VERSION "FR_RE_CANFD"

NS_ :

BS_:

BU_: ADCC ONEBOX RXCU

BO_ 56 VCU_COM_10: 16 RXCU
 SG_ VCU_10_CRC : 7|8@0+ (1,0) [0|255] "" ONEBOX
 SG_ VCU_10_RollgCntr : 11|4@0+ (1,0) [0|14] "" ONEBOX
 SG_ VCU_10_Resd : 15|4@0+ (1,0) [0|15] "" ONEBOX
 SG_ VCU_10_ShiftInProgress : 16|1@0+ (1,0) [0|1] "" Vector__XXX
 SG_ VCU_10_ShiftInProgressValidData : 17|1@0+ (1,0) [0|1] "" Vector__XXX
 SG_ VCU_10_TargetGear : 20|3@0+ (1,0) [0|7] "" Vector__XXX
 SG_ VCU_10_ActualGear : 23|3@0+ (1,0) [0|7] "" Vector__XXX
 SG_ VCU_10_TargetGearValidData : 28|1@0+ (1,0) [0|1] "" Vector__XXX
 SG_ VCU_10_ActualGearValidData : 29|1@0+ (1,0) [0|1] "" Vector__XXX
 SG_ VCU_10_BrakePedalStsValidData : 30|1@0+ (1,0) [0|1] "" Vector__XXX
 SG_ VCU_10_BrakePedalSts : 31|1@0+ (1,0) [0|1] "" Vector__XXX
 SG_ VCU_10_TowingMode : 49|2@0+ (1,0) [0|3] "" ONEBOX
 SG_ HCU_TCUR_GearShiftProgFlag : 63|2@0+ (1,0) [0|3] "" Vector__XXX
 SG_ VCU_10_CRC2 : 71|8@0+ (1,0) [0|255] "" Vector__XXX
 SG_ VCU_10_RollgCntr2 : 75|4@0+ (1,0) [0|14] "" Vector__XXX
 SG_ VCU_10_Resd2 : 79|4@0+ (1,0) [0|15] "" Vector__XXX

BO_ 59 VCU_ONEBOX_11: 64 RXCU
 SG_ VCU_11_CRC1 : 7|8@0+ (1,0) [0|255] "" Vector__XXX
 SG_ VCU_11_RollgCntr1 : 11|4@0+ (1,0) [0|14] "" Vector__XXX
 SG_ VCU_11_Resd1 : 15|4@0+ (1,0) [0|15] "" Vector__XXX
 SG_ VCU_11_IndicatedDriverReqWhlTqFA : 23|16@0+ (1,-32768) [-32768|32767] "NM" Vector__XXX
 SG_ VCU_11_ActWheelTorqueFA : 39|16@0+ (1,-32768) [-32768|32767] "NM" Vector__XXX
 SG_ VCU_11_ActWheelSpdFA : 55|16@0+ (1,-32767) [-32767|32767] "RPM" Vector__XXX
 SG_ VCU_11_CRC2 : 71|8@0+ (1,0) [0|255] "" Vector__XXX
 SG_ VCU_11_RollgCntr2 : 75|4@0+ (1,0) [0|14] "" Vector__XXX
 SG_ VCU_11_Resd2 : 79|4@0+ (1,0) [0|15] "" Vector__XXX
 SG_ VCU_11_IndcdDriverReqWhlTqStsFA : 80|1@0+ (1,0) [0|1] "" Vector__XXX
 SG_ VCU_11_ActWheelTorqueStsFA : 82|2@0+ (1,0) [0|3] "" Vector__XXX
 SG_ VCU_11_ActWheelSpdStsFA : 83|1@0+ (1,0) [0|1] "" Vector__XXX
 SG_ VCU_11_MotorReadyFMCU : 84|1@0+ (1,0) [0|1] "" Vector__XXX
 SG_ VCU_11_IndicatedDriverReqWhlTqRA : 95|16@0+ (1,-32768) [-32768|32767] "NM" Vector__XXX
 SG_ VCU_11_ActWheelTorqueRA : 111|16@0+ (1,-32768) [-32768|32767] "NM" Vector__XXX
 SG_ VCU_11_CRC3 : 135|8@0+ (1,0) [0|255] "" Vector__XXX
 SG_ VCU_11_RollgCntr3 : 139|4@0+ (1,0) [0|14] "" Vector__XXX
 SG_ VCU_11_Resd3 : 143|4@0+ (1,0) [0|15] "" Vector__XXX
 SG_ VCU_11_ActWheelSpdRA : 151|16@0+ (1,-32767) [-32767|32767] "RPM" Vector__XXX
 SG_ VCU_11_IndcdDriverReqWhlTqStsRA : 160|1@0+ (1,0) [0|1] "" Vector__XXX
 SG_ VCU_11_ActWheelTorqueStsRA : 162|2@0+ (1,0) [0|3] "" Vector__XXX
 SG_ VCU_11_MotorReadyRMCU : 163|1@0+ (1,0) [0|1] "" Vector__XXX
 SG_ VCU_11_ActWheelSpdStsRA : 164|1@0+ (1,0) [0|1] "" Vector__XXX
 SG_ VCU_11_MbRegenMaxWheel : 175|16@0+ (1,-32768) [-32768|32767] "NM" Vector__XXX
 SG_ VCU_11_CRC4 : 199|8@0+ (1,0) [0|255] "" ONEBOX
 SG_ VCU_11_RollgCntr4 : 203|4@0+ (1,0) [0|14] "" ONEBOX
 SG_ VCU_11_Resd4 : 207|4@0+ (1,0) [0|15] "" ONEBOX
 SG_ VCU_11_MbRegenWheel : 215|16@0+ (1,-32768) [-32768|32767] "NM" Vector__XXX
 SG_ VCU_11_MbRegenMaxWheelQualifier : 225|2@0+ (1,0) [0|3] "" Vector__XXX
 SG_ VCU_11_MbRegenWheelQualifier : 227|2@0+ (1,0) [0|3] "" Vector__XXX
 SG_ VCU_11_EPBReq : 229|2@0+ (1,0) [0|3] "" ONEBOX
 SG_ VCU_11_GasPedalPosInvalidData : 230|1@0+ (1,0) [0|1] "" Vector__XXX
 SG_ VCU_11_AcceleratorPosRawIVD : 231|1@0+ (1,0) [0|1] "" Vector__XXX
 SG_ VCU_11_GasPedalPosition : 239|10@0+ (0.1,0) [0|100] "%" Vector__XXX
 SG_ VCU_11_AcceleratorPosRaw : 245|10@0+ (0.1,0) [0|100] "%" Vector__XXX
 SG_ VCU_11_EPBReqValid : 251|1@0+ (1,0) [0|1] "" ONEBOX
 SG_ VCU_11_CRC5 : 263|8@0+ (1,0) [0|255] "" Vector__XXX
 SG_ VCU_11_RollgCntr5 : 267|4@0+ (1,0) [0|14] "" Vector__XXX
 SG_ VCU_11_Resd5 : 271|4@0+ (1,0) [0|15] "" Vector__XXX
 SG_ VCU_11_CoastRegenTargetWheelFA : 279|16@0+ (1,-32768) [-32768|32767] "NM" Vector__XXX
 SG_ VCU_11_CoastRegenTargetWheelFAQ : 295|2@0+ (1,0) [0|3] "" Vector__XXX
 SG_ VCU_11_CoastRegenTargetWheelRA : 303|16@0+ (1,-32768) [-32768|32767] "NM" Vector__XXX
 SG_ VCU_11_CoastRegenTargetWheelRAQ : 319|2@0+ (1,0) [0|3] "" Vector__XXX
 SG_ VCU_11_CRC6 : 327|8@0+ (1,0) [0|255] "" Vector__XXX
 SG_ VCU_11_RollgCntr6 : 331|4@0+ (1,0) [0|14] "" Vector__XXX
 SG_ VCU_11_Resd6 : 335|4@0+ (1,0) [0|15] "" Vector__XXX
 SG_ VCU_11_MaxWheelTorqueFA : 343|16@0+ (1,-32768) [-32768|32767] "NM" Vector__XXX
 SG_ VCU_11_MaxWheelTorqueRA : 359|16@0+ (1,-32768) [-32768|32767] "NM" Vector__XXX
 SG_ HCU_11_iTASRearTorque_Max : 375|16@0+ (1,-12000) [-12000|12000] "Nm" Vector__XXX
 SG_ VCU_11_CRC7 : 391|8@0+ (1,0) [0|255] "" Vector__XXX
 SG_ VCU_11_RollgCntr7 : 395|4@0+ (1,0) [0|14] "" Vector__XXX
 SG_ VCU_11_Resd7 : 399|4@0+ (1,0) [0|15] "" Vector__XXX
 SG_ VCU_11_OPDHoldRequest : 405|2@0+ (1,0) [0|3] "" Vector__XXX
 SG_ VCU_11_OPDHydBrkCompenRqSts : 406|1@0+ (1,0) [0|1] "" Vector__XXX
 SG_ VCU_11_OnePedalstatus : 407|1@0+ (1,0) [0|1] "" Vector__XXX
 SG_ VCU_11_OPDHydBrkCompenRqTq : 415|16@0+ (1,-65535) [-65535|0] "NM" Vector__XXX
 SG_ HCU_11_RearWheelDir : 426|2@0+ (1,0) [0|3] "" Vector__XXX
 SG_ VCU_11_DrivingModReq : 431|5@0+ (1,0) [0|31] "" Vector__XXX
 SG_ HCU_11_iTASFrontTorque_Max : 439|16@0+ (1,-12000) [-12000|12000] "Nm" Vector__XXX
 SG_ VCU_11_CRC8 : 455|8@0+ (1,0) [0|255] "" Vector__XXX
 SG_ VCU_11_RollgCntr8 : 459|4@0+ (1,0) [0|14] "" Vector__XXX
 SG_ VCU_11_Resd8 : 463|4@0+ (1,0) [0|15] "" Vector__XXX

BO_ 323 HCU_HW_143h: 48 RXCU
 SG_ HCU_CRC1_143h : 7|8@0+ (1,0) [0|255] "" ADCC
 SG_ HCU_RollgCntr1_143h : 11|4@0+ (1,0) [0|14] "" ADCC
 SG_ HCU_Resd1_143h : 15|4@0+ (1,0) [0|15] "" ADCC
 SG_ HCU_ErrorFb_143h : 18|3@0+ (1,0) [0|7] "" ADCC
 SG_ HCU_GearShiftAvl_143h : 19|1@0+ (1,0) [0|1] "" ADCC
 SG_ HCU_VehWhlReqTqVld_143h : 20|1@0+ (1,0) [0|1] "" ADCC
 SG_ HCU_EGSGearShiftReq_143h : 23|3@0+ (1,0) [0|7] "" ADCC
 SG_ HCU_VehWhlReqTq_143h : 31|16@0+ (1,-32768) [-32768|32767] "" ADCC
 SG_ HCU_CIMGearShiftReq_143h : 49|3@0+ (1,0) [0|7] "" ADCC
 SG_ HCU_ECGPOvrdInvalidData_143h : 61|1@0+ (1,0) [0|1] "" ADCC
 SG_ HCU_ECGPOvrd_143h : 62|1@0+ (1,0) [0|1] "" ADCC
 SG_ HCU_CRC2_143h : 71|8@0+ (1,0) [0|255] "" ADCC
 SG_ HCU_RollgCntr2_143h : 75|4@0+ (1,0) [0|14] "" ADCC
 SG_ HCU_Resd2_143h : 79|4@0+ (1,0) [0|15] "" ADCC
 SG_ HCU_FMCUStandstill_143h : 80|1@0+ (1,0) [0|1] "" ADCC
 SG_ HCU_FMCUModActvSt_143h : 82|2@0+ (1,0) [0|3] "" ADCC
 SG_ HCU_FMCU_SpdSvModAvl_143h : 83|1@0+ (1,0) [0|1] "" ADCC
 SG_ HCU_FMCU_ModeSt_143h : 87|4@0+ (1,0) [0|15] "" ADCC
 SG_ HCU_FMCU_SpdAct_143h : 95|16@0+ (1,-32767) [-32767|32766] "rpm" ADCC
 SG_ HCU_FMCUActRUnfilteredRodSpd : 111|16@0+ (1,-30000) [-30000|35535] "RPM" ADCC
 SG_ HCU_FMCUSpdActVld_143h : 120|1@0+ (1,0) [0|1] "" ADCC
 SG_ HCU_FMCUSpdSVModFlt_143h : 123|3@0+ (1,0) [0|7] "" ADCC
 SG_ HCU_FMCUVehSldSt_143h : 124|1@0+ (1,0) [0|1] "" ADCC
 SG_ HCU_FMCUBlkSt_143h : 127|3@0+ (1,0) [0|7] "" ADCC
 SG_ HCU_CRC3_143h : 135|8@0+ (1,0) [0|255] "" ADCC
 SG_ HCU_RollgCntr3_143h : 139|4@0+ (1,0) [0|14] "" ADCC
 SG_ HCU_Resd3_143h : 143|4@0+ (1,0) [0|15] "" ADCC
 SG_ HCU_ISGStandstill_143h : 144|1@0+ (1,0) [0|1] "" ADCC
 SG_ HCU_ISGModActvSt_143h : 146|2@0+ (1,0) [0|3] "" ADCC
 SG_ HCU_ISGSpdSvModAvl_143h : 147|1@0+ (1,0) [0|1] "" ADCC
 SG_ HCU_ISGF_ModeSt_143h : 151|4@0+ (1,0) [0|15] "" ADCC
 SG_ HCU_ISGF_SpdAct_143h : 159|16@0+ (1,-32767) [-32767|32766] "rpm" ADCC
 SG_ HCU_ISGActRUnfilteredRodSpd : 175|16@0+ (1,-30000) [-30000|35535] "RPM" ADCC
 SG_ HCU_ISGF_SpdActVld_143h : 184|1@0+ (1,0) [0|1] "" ADCC
 SG_ HCU_ISGSpdSVModFlt_143h : 187|3@0+ (1,0) [0|7] "" ADCC
 SG_ HCU_ISGVehSldSt_143h : 188|1@0+ (1,0) [0|1] "" ADCC
 SG_ HCU_ISGBlkSt_143h : 191|3@0+ (1,0) [0|7] "" ADCC
 SG_ HCU_CRC4_143h : 199|8@0+ (1,0) [0|255] "" ADCC
 SG_ HCU_RollgCntr4_143h : 203|4@0+ (1,0) [0|14] "" ADCC
 SG_ HCU_Resd4_143h : 207|4@0+ (1,0) [0|15] "" ADCC
 SG_ HCU_RMCUStandstill_143h : 208|1@0+ (1,0) [0|1] "" ADCC
 SG_ HCU_RMCUModActvSt_143h : 210|2@0+ (1,0) [0|3] "" ADCC
 SG_ HCU_RMCU_SpdSvModAvl_143h : 211|1@0+ (1,0) [0|1] "" ADCC
 SG_ HCU_RMCU_State_143h : 215|4@0+ (1,0) [0|15] "" ADCC
 SG_ HCU_RMCU_Speed_143h : 223|16@0+ (1,-32767) [-32767|32766] "rpm" ADCC
 SG_ HCU_RMCUActRUnfilteredRodSpd : 239|16@0+ (1,-30000) [-30000|35535] "RPM" ADCC
 SG_ HCU_RMCU_SpeedVld_143h : 248|1@0+ (1,0) [0|1] "" ADCC
 SG_ HCU_RMCUSpdSVModFlt_143h : 251|3@0+ (1,0) [0|7] "" ADCC
 SG_ HCU_RMCUVehSldSt_143h : 252|1@0+ (1,0) [0|1] "" ADCC
 SG_ HCU_RMCU_MCUBlkSt_143h : 255|3@0+ (1,0) [0|7] "" ADCC
 SG_ HCU_CRC5_143h : 263|8@0+ (1,0) [0|255] "" ADCC
 SG_ HCU_RollgCntr5_143h : 267|4@0+ (1,0) [0|14] "" ADCC
 SG_ HCU_Resd5_143h : 271|4@0+ (1,0) [0|15] "" ADCC
 SG_ HCU_RMCUReqTq_143h : 279|14@0+ (1,-5000) [-5000|11383] "Nm" ADCC
 SG_ HCU_FMCUReqTq_143h : 281|14@0+ (1,-5000) [-5000|11383] "Nm" ADCC
 SG_ HCU_ISGFReqTq_143h : 299|14@0+ (1,-5000) [-5000|11383] "Nm" ADCC
 SG_ HCU_CRC6_143h : 327|8@0+ (1,0) [0|255] "" ADCC
 SG_ HCU_RollgCntr6_143h : 331|4@0+ (1,0) [0|14] "" ADCC
 SG_ HCU_Resd6_143h : 335|4@0+ (1,0) [0|15] "" ADCC

BO_ 324 HCU_HW_144h: 32 RXCU
 SG_ VCU_MotorDrvCaplTqWhlFA : 23|16@0+ (1,-32768) [-32768|32767] "NM" ADCC
 SG_ VCU_MotorRgnCaplTqWhlFA : 39|16@0+ (1,-32768) [-32768|32767] "NM" ADCC
 SG_ VCU_MotorDrvCaplTqWhlRA : 55|16@0+ (1,-32768) [-32768|32767] "NM" ADCC
 SG_ VCU_MotorRgnCaplTqWhlRA : 87|16@0+ (1,-32768) [-32768|32767] "NM" ADCC

BO_ 555 ONEBOX_3: 48 ONEBOX
 SG_ ONEBOX_3_CRC4 : 199|8@0+ (1,0) [0|255] "" RXCU
 SG_ ONEBOX_3_RollgCntr4 : 203|4@0+ (1,0) [0|14] "" RXCU
 SG_ ONEBOX_3_Resd4 : 207|4@0+ (1,0) [0|15] "" RXCU
 SG_ BrakePedalPressStsValidData : 240|1@0+ (1,0) [0|1] "" RXCU
 SG_ BrakePedalPressSts : 255|2@0+ (1,0) [0|3] "" RXCU

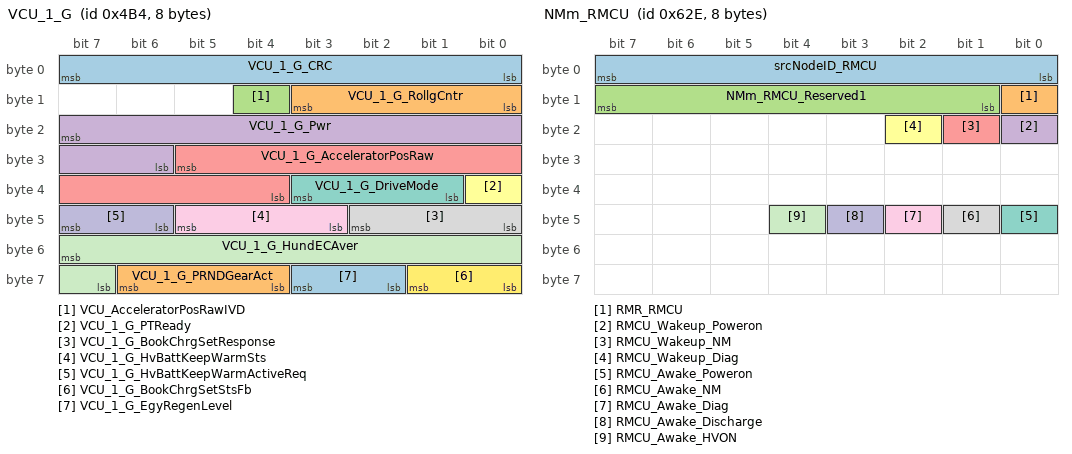
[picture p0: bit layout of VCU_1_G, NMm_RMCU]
BO_ 1204 VCU_1_G: 8 RXCU
 SG_ VCU_1_G_CRC : 7|8@0+ (1,0) [0|255] "" ADCC
 SG_ VCU_1_G_RollgCntr : 11|4@0+ (1,0) [0|14] "" ADCC
 SG_ VCU_AcceleratorPosRawIVD : 12|1@0+ (1,0) [0|1] "" Vector__XXX
 SG_ VCU_1_G_Pwr : 23|10@0+ (1,-500) [-500|500] "" ADCC
 SG_ VCU_1_G_AcceleratorPosRaw : 29|10@0+ (0.1,0) [0|100] "%" ADCC
 SG_ VCU_1_G_PTReady : 32|1@0+ (1,0) [0|1] "" ADCC,ONEBOX
 SG_ VCU_1_G_DriveMode : 35|3@0+ (1,0) [0|7] "" ADCC
 SG_ VCU_1_G_BookChrgSetResponse : 42|3@0+ (1,0) [0|7] "" Vector__XXX
 SG_ VCU_1_G_HvBattKeepWarmSts : 45|3@0+ (1,0) [0|7] "" Vector__XXX
 SG_ VCU_1_G_HvBattKeepWarmActiveReq : 47|2@0+ (1,0) [0|3] "" Vector__XXX
 SG_ VCU_1_G_HundECAver : 55|9@0+ (0.1,0) [0|51] "kwh" ADCC
 SG_ VCU_1_G_BookChrgSetStsFb : 57|2@0+ (1,0) [0|3] "" Vector__XXX
 SG_ VCU_1_G_EgyRegenLevel : 59|2@0+ (1,0) [0|3] "" ADCC
 SG_ VCU_1_G_PRNDGearAct : 62|3@0+ (1,0) [0|7] "" ADCC

BO_ 1209 VCU_2_G: 8 RXCU
 SG_ VCU_2_G_CRC : 7|8@0+ (1,0) [0|255] "" ADCC
 SG_ VCU_2_G_RollgCntr : 11|4@0+ (1,0) [0|14] "" ADCC
 SG_ VCU_2_G_Resd : 15|4@0+ (1,0) [0|15] "" ADCC
 SG_ VCU_2_G_GasPedalPosInvalidData : 24|1@0+ (1,0) [0|1] "" ADCC
 SG_ VCU_2_G_PowerLimit : 25|1@0+ (1,0) [0|1] "" ADCC
 SG_ VCU_2_G_BrakeLightReq : 26|1@0+ (1,0) [0|1] "" ADCC
 SG_ VCU_2_G_VehicleSystemFailure : 27|1@0+ (1,0) [0|1] "" ADCC
 SG_ OnekeyHVOffSuccess_4B9h : 28|1@0+ (1,0) [0|1] "" Vector__XXX
 SG_ VCU_2_G_BootloadSts : 29|1@0+ (1,0) [0|1] "" ADCC
 SG_ VCU_2_G_DischgSts : 30|1@0+ (1,0) [0|1] "" ADCC
 SG_ VCU_2_G_BrakePedalStsValidData : 31|1@0+ (1,0) [0|1] "" ADCC
 SG_ VCU_2_G_ExhibitionMod : 32|1@0+ (1,0) [0|1] "" Vector__XXX
 SG_ VCU_2_G_BrakePedalSts : 36|1@0+ (1,0) [0|1] "" ADCC
 SG_ VCU_2_G_DCDCEnable : 37|1@0+ (1,0) [0|1] "" ADCC
 SG_ VCU_2_G_HVReady : 38|1@0+ (1,0) [0|1] "" ADCC
 SG_ Res_VCU_2_G_Brake_state : 39|1@0+ (1,0) [0|1] "" ADCC
 SG_ VCU_2_G_VCUEnergyflow : 43|4@0+ (1,0) [0|15] "" ADCC
 SG_ VCU_2_G_GasPedalPosition : 49|10@0+ (0.1,0) [0|100] "%" ADCC
 SG_ VCU_2_G_DrvGearShiftFailureIndcn : 53|4@0+ (1,0) [0|15] "" ADCC
 SG_ VCU_2_G_OnekeyHVoffStyle : 55|2@0+ (1,0) [0|3] "" Vector__XXX

BO_ 1582 NMm_RMCU: 8 RXCU
 SG_ srcNodeID_RMCU : 7|8@0+ (1,0) [0|255] "" Vector__XXX
 SG_ RMR_RMCU : 8|1@0+ (1,0) [0|1] "" Vector__XXX
 SG_ NMm_RMCU_Reserved1 : 15|7@0+ (1,0) [0|127] "" Vector__XXX
 SG_ RMCU_Wakeup_Poweron : 16|1@0+ (1,0) [0|1] "" Vector__XXX
 SG_ RMCU_Wakeup_NM : 17|1@0+ (1,0) [0|1] "" Vector__XXX
 SG_ RMCU_Wakeup_Diag : 18|1@0+ (1,0) [0|1] "" Vector__XXX
 SG_ RMCU_Awake_Poweron : 40|1@0+ (1,0) [0|1] "" Vector__XXX
 SG_ RMCU_Awake_NM : 41|1@0+ (1,0) [0|1] "" Vector__XXX
 SG_ RMCU_Awake_Diag : 42|1@0+ (1,0) [0|1] "" Vector__XXX
 SG_ RMCU_Awake_Discharge : 43|1@0+ (1,0) [0|1] "" Vector__XXX
 SG_ RMCU_Awake_HVON : 44|1@0+ (1,0) [0|1] "" Vector__XXX

CM_ SG_ 56 VCU_10_CRC "Profile1A:E2E CRC (SAE J1850 CRC-8) for 8 Bytes
DataID:0x0068";
CM_ SG_ 56 VCU_10_RollgCntr "Profile1A:E2E Rolling message counter(the maximum value of Alive counter is 14)";
CM_ SG_ 56 VCU_10_Resd "Profile1A:E2E Reserved";
CM_ SG_ 56 VCU_10_ShiftInProgress "shifting progress judgement";
CM_ SG_ 56 VCU_10_ShiftInProgressValidData "shifting progress judgement validation";
CM_ SG_ 56 VCU_10_TargetGear "目标档位
Target gear";
CM_ SG_ 56 VCU_10_ActualGear "实际档位
actual gear";
CM_ SG_ 56 VCU_10_TargetGearValidData "目标档位有效性
valid Target gear";
CM_ SG_ 56 VCU_10_ActualGearValidData "实际档位有效性
valid actual gear";
CM_ SG_ 56 VCU_10_BrakePedalStsValidData "制动踏板状态有效";
CM_ SG_ 56 VCU_10_BrakePedalSts "制动踏板状态";
CM_ SG_ 56 VCU_10_TowingMode "拖车模式";
CM_ SG_ 56 HCU_TCUR_GearShiftProgFlag "捷途新增RSCU相关换挡信号The shifting status of rear gearbox（ONEBOX接收）";
CM_ SG_ 56 VCU_10_CRC2 "Profile1A:E2E CRC (SAE J1850 CRC-8) for 8 Bytes
DataID:0x01BB";
CM_ SG_ 56 VCU_10_RollgCntr2 "Profile1A:E2E Rolling message counter(the maximum value of Alive counter is 14)";
CM_ SG_ 56 VCU_10_Resd2 "Profile1A:E2E Reserved";
CM_ SG_ 59 VCU_11_CRC1 "Profile1A:E2E CRC (SAE J1850 CRC-8) for 8 Bytes
DataID:0x0069";
CM_ SG_ 59 VCU_11_RollgCntr1 "Profile1A:E2E Rolling message counter(the maximum value of Alive counter is 14)";
CM_ SG_ 59 VCU_11_Resd1 "Profile1A:E2E Reserved";
CM_ SG_ 59 VCU_11_IndicatedDriverReqWhlTqFA "前轴需求轮端扭矩
Driver request wheel torque at FA";
CM_ SG_ 59 VCU_11_ActWheelTorqueFA "前轴实际轮端扭矩
Actual wheel torque at FA";
CM_ SG_ 59 VCU_11_ActWheelSpdFA "前轮转速（基于电机转速计算）
The motor terminal speed, forward and backward are both sent the positive value";
CM_ SG_ 59 VCU_11_CRC2 "Profile1A:E2E CRC (SAE J1850 CRC-8) for 8 Bytes
DataID:0x006A";
CM_ SG_ 59 VCU_11_RollgCntr2 "Profile1A:E2E Rolling message counter(the maximum value of Alive counter is 14)";
CM_ SG_ 59 VCU_11_Resd2 "Profile1A:E2E Reserved";
CM_ SG_ 59 VCU_11_IndcdDriverReqWhlTqStsFA "前轴需求轮端扭矩有效
Driver request wheel torque status at FA";
CM_ SG_ 59 VCU_11_ActWheelTorqueStsFA "前轴实际轮端扭矩有效
Actual wheel torque status at FA";
CM_ SG_ 59 VCU_11_ActWheelSpdStsFA "前轮转速有效
Actual wheel speed status at FA";
CM_ SG_ 59 VCU_11_MotorReadyFMCU "When the high voltage power-on of the motor is complete and there is no fault, 'Ready' will be sent, other conditions,'Not Ready'will be sent";
CM_ SG_ 59 VCU_11_IndicatedDriverReqWhlTqRA "后轴需求轮端扭矩
Driver request wheel torque at RA";
CM_ SG_ 59 VCU_11_ActWheelTorqueRA "后轴实际轮端扭矩
Actual wheel torque at RA";
CM_ SG_ 59 VCU_11_CRC3 "Profile1A:E2E CRC (SAE J1850 CRC-8) for 8 Bytes
DataID:0x006B";
CM_ SG_ 59 VCU_11_RollgCntr3 "Profile1A:E2E Rolling message counter(the maximum value of Alive counter is 14)";
CM_ SG_ 59 VCU_11_Resd3 "Profile1A:E2E Reserved";
CM_ SG_ 59 VCU_11_ActWheelSpdRA "后轮转速（基于电机转速计算）
The motor terminal speed, forward and backward are both sent the positive value";
CM_ SG_ 59 VCU_11_IndcdDriverReqWhlTqStsRA "后轴需求轮端扭矩有效
Driver request wheel torque status at RA";
CM_ SG_ 59 VCU_11_ActWheelTorqueStsRA "后轴实际轮端扭矩有效
Actual wheel torque status at RA";
CM_ SG_ 59 VCU_11_MotorReadyRMCU "When the high voltage power-on of the motor is complete and there is no fault, 'Ready' will be sent, other conditions,'Not Ready'will be sent";
CM_ SG_ 59 VCU_11_ActWheelSpdStsRA "后轮转速有效
Actual wheel speed status at RA";
CM_ SG_ 59 VCU_11_MbRegenMaxWheel "Max regen torque potential";
CM_ SG_ 59 VCU_11_CRC4 "Profile1A:E2E CRC (SAE J1850 CRC-8) for 8 Bytes
DataID:0x006C";
CM_ SG_ 59 VCU_11_RollgCntr4 "Profile1A:E2E Rolling message counter(the maximum value of Alive counter is 14)";
CM_ SG_ 59 VCU_11_Resd4 "Profile1A:E2E Reserved";
CM_ SG_ 59 VCU_11_MbRegenWheel "Actual regen torque";
CM_ SG_ 59 VCU_11_MbRegenMaxWheelQualifier "Max regen torque potential status";
CM_ SG_ 59 VCU_11_MbRegenWheelQualifier "Actual regen torque status";
CM_ SG_ 59 VCU_11_EPBReq "VCU request EPB function";
CM_ SG_ 59 VCU_11_GasPedalPosition "Driver/Cruise control
This signal including compositive informations which are actual gas pedal position and dummy Cruise control gas pedal position";
CM_ SG_ 59 VCU_11_AcceleratorPosRaw "Raw position of the accelerator pedal (unfiltered). Represents always raw pedal position without any other influcence only mandatory to calculated gradient acceleration pedal.";
CM_ SG_ 59 VCU_11_CRC5 "Profile1A:E2E CRC (SAE J1850 CRC-8) for 8 Bytes
DataID:0x01B7";
CM_ SG_ 59 VCU_11_RollgCntr5 "Profile1A:E2E Rolling message counter(the maximum value of Alive counter is 14)";
CM_ SG_ 59 VCU_11_Resd5 "Profile1A:E2E Reserved";
CM_ SG_ 59 VCU_11_CoastRegenTargetWheelFA "Coast regen target torque at wheel";
CM_ SG_ 59 VCU_11_CoastRegenTargetWheelFAQ "Coast regen target torque status at wheel";
CM_ SG_ 59 VCU_11_CoastRegenTargetWheelRA "Coast regen target torque at wheel";
CM_ SG_ 59 VCU_11_CoastRegenTargetWheelRAQ "Coast regen target torque status at wheel";
CM_ SG_ 59 VCU_11_CRC6 "Profile1A:E2E CRC (SAE J1850 CRC-8) for 8 Bytes
DataID:0x01B6";
CM_ SG_ 59 VCU_11_RollgCntr6 "Profile1A:E2E Rolling message counter(the maximum value of Alive counter is 14)";
CM_ SG_ 59 VCU_11_Resd6 "Profile1A:E2E Reserved";
CM_ SG_ 59 HCU_11_iTASRearTorque_Max "iTAS功能HCU可提供后轴最大扭矩";
CM_ SG_ 59 VCU_11_CRC7 "Profile1A:E2E CRC (SAE J1850 CRC-8) for 8 Bytes
DataID:0x01B5";
CM_ SG_ 59 VCU_11_RollgCntr7 "Profile1A:E2E Rolling message counter(the maximum value of Alive counter is 14)";
CM_ SG_ 59 VCU_11_Resd7 "Profile1A:E2E Reserved";
CM_ SG_ 59 VCU_11_OPDHoldRequest "车辆静止状态请求";
CM_ SG_ 59 VCU_11_OPDHydBrkCompenRqSts "液压制动补偿请求状态";
CM_ SG_ 59 VCU_11_OnePedalstatus "单踏板模式开启状态（底盘专用）";
CM_ SG_ 59 VCU_11_OPDHydBrkCompenRqTq "液压制动补偿力矩";
CM_ SG_ 59 HCU_11_RearWheelDir "HCU反馈后轴扭矩方向";
CM_ SG_ 59 VCU_11_DrivingModReq "HCU给IPB映射驾驶模式";
CM_ SG_ 59 HCU_11_iTASFrontTorque_Max "iTAS功能HCU可提供前轴最大扭矩";
CM_ SG_ 59 VCU_11_CRC8 "Profile1A:E2E CRC (SAE J1850 CRC-8) for 8 Bytes
DataID:0x01B4";
CM_ SG_ 59 VCU_11_RollgCntr8 "Profile1A:E2E Rolling message counter(the maximum value of Alive counter is 14)";
CM_ SG_ 59 VCU_11_Resd8 "Profile1A:E2E Reserved";
CM_ SG_ 323 HCU_CRC1_143h "Profile1A:E2E CRC (SAE J1850 CRC-8) for 8 Bytes
DataID:0x00FA";
CM_ SG_ 323 HCU_RollgCntr1_143h "Profile1A:E2E Rolling message counter(the maximum value of Alive counter is 14)";
CM_ SG_ 323 HCU_Resd1_143h "Profile1A:E2E Reserved";
CM_ SG_ 323 HCU_ErrorFb_143h "HCU上报故障原因
0x0:No error
0x1: ADS请求有效位无效
0x2: 高压故障
0x2: MCU故障
0x3: BMS故障
0x7:ADS E2E 故障或者time out";
CM_ SG_ 323 HCU_GearShiftAvl_143h "挡位切换可用状态";
CM_ SG_ 323 HCU_VehWhlReqTqVld_143h "整车需求轮端扭矩有效";
CM_ SG_ 323 HCU_EGSGearShiftReq_143h "电子换挡器挡位请求";
CM_ SG_ 323 HCU_VehWhlReqTq_143h "整车需求轮端扭矩";
CM_ SG_ 323 HCU_CIMGearShiftReq_143h "电子换挡器挡位请求";
CM_ SG_ 323 HCU_ECGPOvrdInvalidData_143h "标识驾驶员扭矩高于ACC请求扭矩有效性";
CM_ SG_ 323 HCU_ECGPOvrd_143h "标识驾驶员扭矩高于ACC请求扭矩";
CM_ SG_ 323 HCU_CRC2_143h "Profile1A:E2E CRC (SAE J1850 CRC-8) for 8 Bytes
DataID:0x00FB";
CM_ SG_ 323 HCU_RollgCntr2_143h "Profile1A:E2E Rolling message counter(the maximum value of Alive counter is 14)";
CM_ SG_ 323 HCU_Resd2_143h "Profile1A:E2E Reserved";
CM_ SG_ 323 HCU_FMCUStandstill_143h "MCU standstill状态";
CM_ SG_ 323 HCU_FMCUModActvSt_143h "MCU模式激活状态
0x0: 扭矩模式
0x1: 转速模式
0x2: SV模式";
CM_ SG_ 323 HCU_FMCU_SpdSvModAvl_143h "转速模式可用状态";
CM_ SG_ 323 HCU_FMCU_ModeSt_143h "前驱动电机状态信号
actual state of FMCU motor
FMCU状态信号
拆帧转发至GL 网段
ID 0x397（FLZCU_16）Bit116-119";
CM_ SG_ 323 HCU_FMCU_SpdAct_143h "FMCU motor actual speed
前驱动电机实际转速（EM2转速）";
CM_ SG_ 323 HCU_FMCUActRUnfilteredRodSpd "MCU滤波前实际转速";
CM_ SG_ 323 HCU_FMCUSpdActVld_143h "VCU转发FMCU电机实际转速有效性";
CM_ SG_ 323 HCU_FMCUSpdSVModFlt_143h "MCU转速模式故障原因
0x0: 无故障
0x1: 输出扭矩绝对值过大故障";
CM_ SG_ 323 HCU_FMCUVehSldSt_143h "驱动电机判断车辆是否溜车";
CM_ SG_ 323 HCU_FMCUBlkSt_143h "MCU卡停状态";
CM_ SG_ 323 HCU_CRC3_143h "Profile1A:E2E CRC (SAE J1850 CRC-8) for 8 Bytes
DataID:0x01BA";
CM_ SG_ 323 HCU_RollgCntr3_143h "Profile1A:E2E Rolling message counter(the maximum value of Alive counter is 14)";
CM_ SG_ 323 HCU_Resd3_143h "Profile1A:E2E Reserved";
CM_ SG_ 323 HCU_ISGStandstill_143h "发电机 standstill状态";
CM_ SG_ 323 HCU_ISGModActvSt_143h "发电机模式激活状态
0x0: 扭矩模式
0x1: 转速模式
0x2: SV模式";
CM_ SG_ 323 HCU_ISGSpdSvModAvl_143h "发电机转速模式可用状态";
CM_ SG_ 323 HCU_ISGF_ModeSt_143h "前发电机模式状态
actual state of ISG motor";
CM_ SG_ 323 HCU_ISGF_SpdAct_143h "前发电机实际转速
ISG motor actual speed";
CM_ SG_ 323 HCU_ISGActRUnfilteredRodSpd "发电机滤波前实际转速";
CM_ SG_ 323 HCU_ISGF_SpdActVld_143h "VCU转发ISGF电机实际转速有效性";
CM_ SG_ 323 HCU_ISGSpdSVModFlt_143h "发电机转速模式故障原因
0x0: 无故障
0x1: 输出扭矩绝对值过大故障";
CM_ SG_ 323 HCU_ISGVehSldSt_143h "发电机判断车辆是否溜车";
CM_ SG_ 323 HCU_ISGBlkSt_143h "发电机卡停状态";
CM_ SG_ 323 HCU_CRC4_143h "Profile1A:E2E CRC (SAE J1850 CRC-8) for 8 Bytes
DataID:0x00FC";
CM_ SG_ 323 HCU_RollgCntr4_143h "Profile1A:E2E Rolling message counter(the maximum value of Alive counter is 14)";
CM_ SG_ 323 HCU_Resd4_143h "Profile1A:E2E Reserved";
CM_ SG_ 323 HCU_RMCUStandstill_143h "MCU standstill状态";
CM_ SG_ 323 HCU_RMCUModActvSt_143h "MCU模式激活状态
0x0: 扭矩模式
0x1: 转速模式
0x2: SV模式";
CM_ SG_ 323 HCU_RMCU_SpdSvModAvl_143h "转速模式可用状态";
CM_ SG_ 323 HCU_RMCU_State_143h "后驱动电机状态
actual state of RMCU motor
拆帧至GL网段
ID 0x397(FLZCU_16)Bit112-115";
CM_ SG_ 323 HCU_RMCU_Speed_143h "后驱动电机转速RMCU motor actual speed";
CM_ SG_ 323 HCU_RMCUActRUnfilteredRodSpd "MCU滤波前实际转速";
CM_ SG_ 323 HCU_RMCU_SpeedVld_143h "VCU转发RMCU电机实际转速有效性";
CM_ SG_ 323 HCU_RMCUSpdSVModFlt_143h "MCU转速模式故障原因
0x0: 无故障
0x1: 输出扭矩绝对值过大故障";
CM_ SG_ 323 HCU_RMCUVehSldSt_143h "驱动电机判断车辆是否溜车";
CM_ SG_ 323 HCU_RMCU_MCUBlkSt_143h "MCU卡停状态";
CM_ SG_ 323 HCU_CRC5_143h "Profile1A:E2E CRC (SAE J1850 CRC-8) for 8 Bytes
DataID:0x01B9";
CM_ SG_ 323 HCU_RollgCntr5_143h "Profile1A:E2E Rolling message counter(the maximum value of Alive counter is 14)";
CM_ SG_ 323 HCU_Resd5_143h "Profile1A:E2E Reserved";
CM_ SG_ 323 HCU_RMCUReqTq_143h "MCU需求扭矩";
CM_ SG_ 323 HCU_FMCUReqTq_143h "MCU需求扭矩";
CM_ SG_ 323 HCU_ISGFReqTq_143h "MCU需求扭矩";
CM_ SG_ 323 HCU_CRC6_143h "Profile1A:E2E CRC (SAE J1850 CRC-8) for 8 Bytes
DataID:0x01B8";
CM_ SG_ 323 HCU_RollgCntr6_143h "Profile1A:E2E Rolling message counter(the maximum value of Alive counter is 14)";
CM_ SG_ 323 HCU_Resd6_143h "Profile1A:E2E Reserved";
CM_ SG_ 324 VCU_MotorDrvCaplTqWhlFA "前轴电机轮端驱动扭矩能力";
CM_ SG_ 324 VCU_MotorRgnCaplTqWhlFA "前轴电机轮端负扭矩能力";
CM_ SG_ 324 VCU_MotorDrvCaplTqWhlRA "后轴电机轮端驱动扭矩能力";
CM_ SG_ 324 VCU_MotorRgnCaplTqWhlRA "后轴电机轮端负扭矩能力";
CM_ SG_ 555 ONEBOX_3_CRC4 "Profile1A:E2E CRC (SAE J1850 CRC-8) for 8 Bytes
DataID:0x0050";
CM_ SG_ 555 ONEBOX_3_RollgCntr4 "Profile1A:E2E Rolling message counter(the maximum value of Alive counter is 14)";
CM_ SG_ 555 ONEBOX_3_Resd4 "Profile1A:E2E Reserved";
CM_ SG_ 555 BrakePedalPressStsValidData "刹车踏板有效信号
取消制动踏板硬开关新增";
CM_ SG_ 555 BrakePedalPressSts "刹车踏板状态信号   
取消制动踏板硬开关新增";
CM_ SG_ 1204 VCU_1_G_CRC "Profile1A:E2E CRC (SAE J1850 CRC-8) for 8 Bytes
DataID:0x005C";
CM_ SG_ 1204 VCU_1_G_RollgCntr "Profile1A:E2E Rolling message counter(the maximum value of Alive counter is 14)";
CM_ SG_ 1204 VCU_1_G_Pwr "instant power（股份信号D01未使用）";
CM_ SG_ 1204 VCU_1_G_AcceleratorPosRaw "真实油门开度
Raw position of the accelerator pedal (unfiltered). Represents always raw pedal position without any other influcence only mandatory to calculated gradient acceleration pedal.";
CM_ SG_ 1204 VCU_1_G_PTReady "PT Ready indication";
CM_ SG_ 1204 VCU_1_G_DriveMode "Driving modes（股份信号D01未使用）";
CM_ SG_ 1204 VCU_1_G_HvBattKeepWarmSts "插枪保温状态";
CM_ SG_ 1204 VCU_1_G_HvBattKeepWarmActiveReq "插枪保温开启请求";
CM_ SG_ 1204 VCU_1_G_HundECAver "average consumption per hundred KM（股份信号D01未使用）";
CM_ SG_ 1204 VCU_1_G_BookChrgSetStsFb "预约充电设置与否状态反馈";
CM_ SG_ 1204 VCU_1_G_EgyRegenLevel "power regeneration level（股份信号D01未使用）";
CM_ SG_ 1204 VCU_1_G_PRNDGearAct "Gear indication";
CM_ SG_ 1209 VCU_2_G_CRC "Profile1A:E2E CRC (SAE J1850 CRC-8) for 8 Bytes
DataID:0x005D";
CM_ SG_ 1209 VCU_2_G_RollgCntr "Profile1A:E2E Rolling message counter(the maximum value of Alive counter is 14)";
CM_ SG_ 1209 VCU_2_G_Resd "Profile1A:E2E Reserved";
CM_ SG_ 1209 VCU_2_G_PowerLimit "power limitation indication";
CM_ SG_ 1209 VCU_2_G_BrakeLightReq "break light during regeneration (calibration)";
CM_ SG_ 1209 VCU_2_G_VehicleSystemFailure "vehicle system failure";
CM_ SG_ 1209 OnekeyHVOffSuccess_4B9h "物理开关一键下高压状态反馈（法规要求）";
CM_ SG_ 1209 VCU_2_G_BootloadSts "0x1:software flash";
CM_ SG_ 1209 VCU_2_G_DischgSts "ICM indication Discharging state";
CM_ SG_ 1209 VCU_2_G_BrakePedalStsValidData "制动踏板状态有效";
CM_ SG_ 1209 VCU_2_G_BrakePedalSts "制动踏板状态";
CM_ SG_ 1209 VCU_2_G_HVReady "HV Ready";
CM_ SG_ 1209 Res_VCU_2_G_Brake_state "break signal

RVM legal request";
CM_ SG_ 1209 VCU_2_G_GasPedalPosition "Driver/Cruise control
This signal including compositive informations which are actual gas pedal position and dummy Cruise control gas pedal position";
CM_ SG_ 1209 VCU_2_G_DrvGearShiftFailureIndcn "0x0:No Indication；（仪表不显示）
0x1:换挡请踩刹车；（驾驶员期望换挡但没有踩下制动踏板时以此提示驾驶员。触发后驾驶员踩下制动踏板或4s后停发）
0x2:换挡车速过高
0x3:换挡请拔下充电枪（P挡且交流枪连接或直流枪连接时拨动换挡杆）
0x4: EPB无法锁止
0x5: EPB无法释放
0x6: 无法切换行驶方向（车辆D/R挡时EGS通讯丢失）
0x7: 换挡杆需求维修（EGS通讯丢失超过3个驾驶循环或发生故障AllWarningInfo!=0x0）";
CM_ SG_ 1209 VCU_2_G_OnekeyHVoffStyle "物理开关一键下高压触发类型";
CM_ SG_ 1582 RMR_RMCU "If set to 1 to force the network management of all other nodes on the bus into the re-peat message state.";
CM_ SG_ 1582 RMCU_Wakeup_Poweron "KL15 ON";
CM_ SG_ 1582 RMCU_Wakeup_NM "NM报文";
CM_ SG_ 1582 RMCU_Wakeup_Diag "Wakeup Source3 Reserved";
CM_ SG_ 1582 RMCU_Awake_Poweron "KL15 ON";
CM_ SG_ 1582 RMCU_Awake_NM "Awake Reason2 Reserved";
CM_ SG_ 1582 RMCU_Awake_Diag "接收到本部件相关的诊断报文";
CM_ SG_ 1582 RMCU_Awake_Discharge "放电中且放电未超时";
CM_ SG_ 1582 RMCU_Awake_HVON "整车处于高压状态";

BA_DEF_ BU_ "ILused" ENUM "No","Yes";
BA_DEF_ BU_ "NmNode" ENUM "No","Yes";
BA_DEF_ BU_ "NodeLayerModules" STRING ;
BA_DEF_ "Baudrate" INT 0 1000000;
BA_DEF_ "BaudrateCANFD" INT 1000000 10000000;
BA_DEF_ "BusType" STRING ;
BA_DEF_ "DBName" STRING ;
BA_DEF_ "NmBaseAddress" HEX 1536 1663;
BA_DEF_ "NmMessageCount" INT 0 255;
BA_DEF_ "ProtocolType" STRING ;
BA_DEF_ SG_ "ASIL" ENUM "QM","A","B","C","D";
BA_DEF_ SG_ "E2EDataLength" INT 0 65535;
BA_DEF_ SG_ "GenSigInactiveValue" HEX 0 80000000;
BA_DEF_ SG_ "GenSigInvalidValue" HEX 0 281474976710655;
BA_DEF_ SG_ "GenSigStartValue" HEX 0 80000000;
BA_DEF_ SG_ "GenSigSendType" ENUM "Cyclic","OnWrite","OnWriteWithRepetition","OnChange","OnChangeWithRepetition","IfActive","IfActiveWithRepetition","NoSigSendType";
BA_DEF_ BO_ "CANFD_BRS" ENUM "0","1";
BA_DEF_ BO_ "DiagUudtResponse" ENUM "True","False";
BA_DEF_ BO_ "GenMsgCycleTime" INT 0 65535;
BA_DEF_ BO_ "GenMsgCycleTimeFast" INT 0 65535;
BA_DEF_ BO_ "GenMsgDelayTime" INT 0 65535;
BA_DEF_ BO_ "GenMsgILSupport" ENUM "No","Yes";
BA_DEF_ BO_ "GenMsgNrOfRepetition" INT 0 255;
BA_DEF_ BO_ "GenMsgSendType" ENUM "Cyclic","Event","IfActive","CE","CA","NoMsgSendType";
BA_DEF_ BO_ "MsgType" ENUM "IL","NM","DIAG","APPL";
BA_DEF_ BO_ "Msg_ASIL" ENUM "vector_leerstring","QM","A","B","C","D";
BA_DEF_ BO_ "NmAsrMessage" ENUM "No","Yes";
BA_DEF_ BO_ "NmMessage" ENUM "No","Yes";
BA_DEF_ BO_ "SCP_AuthInfoTxLength" INT 9 512;
BA_DEF_ BO_ "SCP_FreshnessValueLength" INT 0 512;
BA_DEF_ BO_ "SCP_FreshnessValueTxLength" INT 0 512;
BA_DEF_ BO_ "VFrameFormat" ENUM "StandardCAN","ExtendedCAN","reserved","J1939PG","reserved","reserved","reserved","reserved","reserved","reserved","reserved","reserved","reserved","reserved","StandardCAN_FD","ExtendedCAN_FD";
BA_DEF_DEF_ "ILused" "Yes";
BA_DEF_DEF_ "NmNode" "No";
BA_DEF_DEF_ "NodeLayerModules" "CANoeILNLSPA.dll";
BA_DEF_DEF_ "Baudrate" 500000;
BA_DEF_DEF_ "BaudrateCANFD" 2000000;
BA_DEF_DEF_ "BusType" "CAN";
BA_DEF_DEF_ "DBName" "CAN";
BA_DEF_DEF_ "NmBaseAddress" 1536;
BA_DEF_DEF_ "NmMessageCount" 128;
BA_DEF_DEF_ "ProtocolType" "CAN";
BA_DEF_DEF_ "ASIL" "QM";
BA_DEF_DEF_ "E2EDataLength" 64;
BA_DEF_DEF_ "GenSigInactiveValue" 0;
BA_DEF_DEF_ "GenSigInvalidValue" 0;
BA_DEF_DEF_ "GenSigStartValue" 0;
BA_DEF_DEF_ "GenSigSendType" "NoSigSendType";
BA_DEF_DEF_ "CANFD_BRS" "1";
BA_DEF_DEF_ "DiagUudtResponse" "True";
BA_DEF_DEF_ "GenMsgCycleTime" 0;
BA_DEF_DEF_ "GenMsgCycleTimeFast" 0;
BA_DEF_DEF_ "GenMsgDelayTime" 0;
BA_DEF_DEF_ "GenMsgILSupport" "Yes";
BA_DEF_DEF_ "GenMsgNrOfRepetition" 0;
BA_DEF_DEF_ "GenMsgSendType" "Cyclic";
BA_DEF_DEF_ "MsgType" "IL";
BA_DEF_DEF_ "Msg_ASIL" "vector_leerstring";
BA_DEF_DEF_ "NmAsrMessage" "No";
BA_DEF_DEF_ "NmMessage" "No";
BA_DEF_DEF_ "SCP_AuthInfoTxLength" 28;
BA_DEF_DEF_ "SCP_FreshnessValueLength" 48;
BA_DEF_DEF_ "SCP_FreshnessValueTxLength" 4;
BA_DEF_DEF_ "VFrameFormat" "J1939PG";
BA_ "BusType" "CAN FD";
BA_ "DBName" "FR_RE_CANFD";
BA_ "ILused" BU_ ADCC 0;
BA_ "NodeLayerModules" BU_ ONEBOX "CANoeILNLVector.dll";
BA_ "ILused" BU_ ONEBOX 0;
BA_ "ILused" BU_ RXCU 0;
BA_ "GenMsgCycleTime" BO_ 56 10;
BA_ "VFrameFormat" BO_ 56 14;
BA_ "GenMsgCycleTime" BO_ 59 10;
BA_ "VFrameFormat" BO_ 59 14;
BA_ "GenMsgCycleTime" BO_ 323 10;
BA_ "VFrameFormat" BO_ 323 14;
BA_ "GenMsgCycleTime" BO_ 324 10;
BA_ "VFrameFormat" BO_ 324 14;
BA_ "GenMsgCycleTime" BO_ 555 20;
BA_ "VFrameFormat" BO_ 555 14;
BA_ "GenMsgCycleTime" BO_ 1204 100;
BA_ "VFrameFormat" BO_ 1204 14;
BA_ "GenMsgCycleTime" BO_ 1209 100;
BA_ "VFrameFormat" BO_ 1209 14;
BA_ "GenMsgCycleTime" BO_ 1582 1000;
BA_ "NmMessage" BO_ 1582 1;
BA_ "DiagUudtResponse" BO_ 1582 1;
BA_ "MsgType" BO_ 1582 1;
BA_ "NmAsrMessage" BO_ 1582 1;
BA_ "GenMsgILSupport" BO_ 1582 0;
BA_ "VFrameFormat" BO_ 1582 0;
BA_ "GenSigSendType" SG_ 56 VCU_10_CRC 0;
BA_ "GenSigSendType" SG_ 56 VCU_10_RollgCntr 0;
BA_ "GenSigSendType" SG_ 56 VCU_10_Resd 0;
BA_ "GenSigSendType" SG_ 56 VCU_10_ShiftInProgress 0;
BA_ "GenSigSendType" SG_ 56 VCU_10_ShiftInProgressValidData 0;
BA_ "ASIL" SG_ 56 VCU_10_TargetGear 2;
BA_ "GenSigSendType" SG_ 56 VCU_10_TargetGear 0;
BA_ "ASIL" SG_ 56 VCU_10_ActualGear 2;
BA_ "GenSigSendType" SG_ 56 VCU_10_ActualGear 0;
BA_ "ASIL" SG_ 56 VCU_10_TargetGearValidData 2;
BA_ "GenSigSendType" SG_ 56 VCU_10_TargetGearValidData 0;
BA_ "ASIL" SG_ 56 VCU_10_ActualGearValidData 2;
BA_ "GenSigSendType" SG_ 56 VCU_10_ActualGearValidData 0;
BA_ "GenSigSendType" SG_ 56 VCU_10_BrakePedalStsValidData 0;
BA_ "ASIL" SG_ 56 VCU_10_BrakePedalSts 2;
BA_ "GenSigSendType" SG_ 56 VCU_10_BrakePedalSts 0;
BA_ "ASIL" SG_ 56 VCU_10_TowingMode 2;
BA_ "GenSigSendType" SG_ 56 VCU_10_TowingMode 0;
BA_ "ASIL" SG_ 56 HCU_TCUR_GearShiftProgFlag 2;
BA_ "GenSigSendType" SG_ 56 HCU_TCUR_GearShiftProgFlag 0;
BA_ "GenSigSendType" SG_ 56 VCU_10_CRC2 0;
BA_ "GenSigSendType" SG_ 56 VCU_10_RollgCntr2 0;
BA_ "GenSigSendType" SG_ 56 VCU_10_Resd2 0;
BA_ "GenSigSendType" SG_ 59 VCU_11_CRC1 0;
BA_ "GenSigSendType" SG_ 59 VCU_11_RollgCntr1 0;
BA_ "GenSigSendType" SG_ 59 VCU_11_Resd1 0;
BA_ "GenSigStartValue" SG_ 59 VCU_11_IndicatedDriverReqWhlTqFA 32768;
BA_ "ASIL" SG_ 59 VCU_11_IndicatedDriverReqWhlTqFA 3;
BA_ "GenSigSendType" SG_ 59 VCU_11_IndicatedDriverReqWhlTqFA 0;
BA_ "GenSigStartValue" SG_ 59 VCU_11_ActWheelTorqueFA 32768;
BA_ "ASIL" SG_ 59 VCU_11_ActWheelTorqueFA 2;
BA_ "GenSigSendType" SG_ 59 VCU_11_ActWheelTorqueFA 0;
BA_ "GenSigInvalidValue" SG_ 59 VCU_11_ActWheelSpdFA 65535;
BA_ "GenSigStartValue" SG_ 59 VCU_11_ActWheelSpdFA 32767;
BA_ "GenSigSendType" SG_ 59 VCU_11_ActWheelSpdFA 0;
BA_ "GenSigSendType" SG_ 59 VCU_11_CRC2 0;
BA_ "GenSigSendType" SG_ 59 VCU_11_RollgCntr2 0;
BA_ "GenSigSendType" SG_ 59 VCU_11_Resd2 0;
BA_ "GenSigStartValue" SG_ 59 VCU_11_IndcdDriverReqWhlTqStsFA 1;
BA_ "ASIL" SG_ 59 VCU_11_IndcdDriverReqWhlTqStsFA 2;
BA_ "GenSigSendType" SG_ 59 VCU_11_IndcdDriverReqWhlTqStsFA 0;
BA_ "GenSigStartValue" SG_ 59 VCU_11_ActWheelTorqueStsFA 1;
BA_ "ASIL" SG_ 59 VCU_11_ActWheelTorqueStsFA 3;
BA_ "GenSigSendType" SG_ 59 VCU_11_ActWheelTorqueStsFA 0;
BA_ "GenSigStartValue" SG_ 59 VCU_11_ActWheelSpdStsFA 1;
BA_ "GenSigSendType" SG_ 59 VCU_11_ActWheelSpdStsFA 0;
BA_ "GenSigSendType" SG_ 59 VCU_11_MotorReadyFMCU 0;
BA_ "GenSigStartValue" SG_ 59 VCU_11_IndicatedDriverReqWhlTqRA 32768;
BA_ "ASIL" SG_ 59 VCU_11_IndicatedDriverReqWhlTqRA 3;
BA_ "GenSigSendType" SG_ 59 VCU_11_IndicatedDriverReqWhlTqRA 0;
BA_ "GenSigStartValue" SG_ 59 VCU_11_ActWheelTorqueRA 32768;
BA_ "ASIL" SG_ 59 VCU_11_ActWheelTorqueRA 2;
BA_ "GenSigSendType" SG_ 59 VCU_11_ActWheelTorqueRA 0;
BA_ "GenSigSendType" SG_ 59 VCU_11_CRC3 0;
BA_ "GenSigSendType" SG_ 59 VCU_11_RollgCntr3 0;
BA_ "GenSigSendType" SG_ 59 VCU_11_Resd3 0;
BA_ "GenSigInvalidValue" SG_ 59 VCU_11_ActWheelSpdRA 65535;
BA_ "GenSigStartValue" SG_ 59 VCU_11_ActWheelSpdRA 32767;
BA_ "GenSigSendType" SG_ 59 VCU_11_ActWheelSpdRA 0;
BA_ "GenSigStartValue" SG_ 59 VCU_11_IndcdDriverReqWhlTqStsRA 1;
BA_ "ASIL" SG_ 59 VCU_11_IndcdDriverReqWhlTqStsRA 2;
BA_ "GenSigSendType" SG_ 59 VCU_11_IndcdDriverReqWhlTqStsRA 0;
BA_ "GenSigStartValue" SG_ 59 VCU_11_ActWheelTorqueStsRA 1;
BA_ "GenSigSendType" SG_ 59 VCU_11_ActWheelTorqueStsRA 0;
BA_ "GenSigSendType" SG_ 59 VCU_11_MotorReadyRMCU 0;
BA_ "GenSigStartValue" SG_ 59 VCU_11_ActWheelSpdStsRA 1;
BA_ "GenSigSendType" SG_ 59 VCU_11_ActWheelSpdStsRA 0;
BA_ "GenSigStartValue" SG_ 59 VCU_11_MbRegenMaxWheel 32768;
BA_ "ASIL" SG_ 59 VCU_11_MbRegenMaxWheel 3;
BA_ "GenSigSendType" SG_ 59 VCU_11_MbRegenMaxWheel 0;
BA_ "GenSigSendType" SG_ 59 VCU_11_CRC4 0;
BA_ "GenSigSendType" SG_ 59 VCU_11_RollgCntr4 0;
BA_ "GenSigSendType" SG_ 59 VCU_11_Resd4 0;
BA_ "GenSigStartValue" SG_ 59 VCU_11_MbRegenWheel 32768;
BA_ "ASIL" SG_ 59 VCU_11_MbRegenWheel 3;
BA_ "GenSigSendType" SG_ 59 VCU_11_MbRegenWheel 0;
BA_ "GenSigSendType" SG_ 59 VCU_11_MbRegenMaxWheelQualifier 0;
BA_ "GenSigSendType" SG_ 59 VCU_11_MbRegenWheelQualifier 0;
BA_ "ASIL" SG_ 59 VCU_11_EPBReq 3;
BA_ "GenSigSendType" SG_ 59 VCU_11_EPBReq 0;
BA_ "ASIL" SG_ 59 VCU_11_GasPedalPosInvalidData 2;
BA_ "GenSigSendType" SG_ 59 VCU_11_GasPedalPosInvalidData 0;
BA_ "ASIL" SG_ 59 VCU_11_AcceleratorPosRawIVD 2;
BA_ "GenSigSendType" SG_ 59 VCU_11_AcceleratorPosRawIVD 0;
BA_ "GenSigInvalidValue" SG_ 59 VCU_11_GasPedalPosition 1023;
BA_ "ASIL" SG_ 59 VCU_11_GasPedalPosition 2;
BA_ "GenSigSendType" SG_ 59 VCU_11_GasPedalPosition 0;
BA_ "GenSigInvalidValue" SG_ 59 VCU_11_AcceleratorPosRaw 1023;
BA_ "ASIL" SG_ 59 VCU_11_AcceleratorPosRaw 2;
BA_ "GenSigSendType" SG_ 59 VCU_11_AcceleratorPosRaw 0;
BA_ "GenSigSendType" SG_ 59 VCU_11_EPBReqValid 0;
BA_ "GenSigSendType" SG_ 59 VCU_11_CRC5 0;
BA_ "GenSigSendType" SG_ 59 VCU_11_RollgCntr5 0;
BA_ "GenSigSendType" SG_ 59 VCU_11_Resd5 0;
BA_ "GenSigStartValue" SG_ 59 VCU_11_CoastRegenTargetWheelFA 32768;
BA_ "GenSigSendType" SG_ 59 VCU_11_CoastRegenTargetWheelFA 0;
BA_ "GenSigSendType" SG_ 59 VCU_11_CoastRegenTargetWheelFAQ 0;
BA_ "GenSigStartValue" SG_ 59 VCU_11_CoastRegenTargetWheelRA 32768;
BA_ "GenSigSendType" SG_ 59 VCU_11_CoastRegenTargetWheelRA 0;
BA_ "GenSigSendType" SG_ 59 VCU_11_CoastRegenTargetWheelRAQ 0;
BA_ "GenSigSendType" SG_ 59 VCU_11_CRC6 0;
BA_ "GenSigSendType" SG_ 59 VCU_11_RollgCntr6 0;
BA_ "GenSigSendType" SG_ 59 VCU_11_Resd6 0;
BA_ "GenSigStartValue" SG_ 59 VCU_11_MaxWheelTorqueFA 32768;
BA_ "GenSigSendType" SG_ 59 VCU_11_MaxWheelTorqueFA 0;
BA_ "GenSigStartValue" SG_ 59 VCU_11_MaxWheelTorqueRA 32768;
BA_ "GenSigSendType" SG_ 59 VCU_11_MaxWheelTorqueRA 0;
BA_ "GenSigInvalidValue" SG_ 59 HCU_11_iTASRearTorque_Max 65535;
BA_ "GenSigSendType" SG_ 59 HCU_11_iTASRearTorque_Max 0;
BA_ "GenSigSendType" SG_ 59 VCU_11_CRC7 0;
BA_ "GenSigSendType" SG_ 59 VCU_11_RollgCntr7 0;
BA_ "GenSigSendType" SG_ 59 VCU_11_Resd7 0;
BA_ "GenSigSendType" SG_ 59 VCU_11_OPDHoldRequest 0;
BA_ "GenSigSendType" SG_ 59 VCU_11_OPDHydBrkCompenRqSts 0;
BA_ "GenSigSendType" SG_ 59 VCU_11_OnePedalstatus 0;
BA_ "GenSigStartValue" SG_ 59 VCU_11_OPDHydBrkCompenRqTq 65535;
BA_ "GenSigSendType" SG_ 59 VCU_11_OPDHydBrkCompenRqTq 0;
BA_ "GenSigSendType" SG_ 59 HCU_11_RearWheelDir 0;
BA_ "GenSigSendType" SG_ 59 VCU_11_DrivingModReq 0;
BA_ "GenSigInvalidValue" SG_ 59 HCU_11_iTASFrontTorque_Max 65535;
BA_ "GenSigSendType" SG_ 59 HCU_11_iTASFrontTorque_Max 0;
BA_ "GenSigSendType" SG_ 59 VCU_11_CRC8 0;
BA_ "GenSigSendType" SG_ 59 VCU_11_RollgCntr8 0;
BA_ "GenSigSendType" SG_ 59 VCU_11_Resd8 0;
BA_ "GenSigSendType" SG_ 323 HCU_CRC1_143h 0;
BA_ "GenSigSendType" SG_ 323 HCU_RollgCntr1_143h 0;
BA_ "GenSigSendType" SG_ 323 HCU_Resd1_143h 0;
BA_ "GenSigSendType" SG_ 323 HCU_ErrorFb_143h 0;
BA_ "ASIL" SG_ 323 HCU_GearShiftAvl_143h 3;
BA_ "GenSigSendType" SG_ 323 HCU_GearShiftAvl_143h 0;
BA_ "GenSigSendType" SG_ 323 HCU_VehWhlReqTqVld_143h 0;
BA_ "GenSigSendType" SG_ 323 HCU_EGSGearShiftReq_143h 0;
BA_ "GenSigSendType" SG_ 323 HCU_VehWhlReqTq_143h 0;
BA_ "ASIL" SG_ 323 HCU_CIMGearShiftReq_143h 3;
BA_ "GenSigSendType" SG_ 323 HCU_CIMGearShiftReq_143h 0;
BA_ "GenSigSendType" SG_ 323 HCU_ECGPOvrdInvalidData_143h 0;
BA_ "GenSigSendType" SG_ 323 HCU_ECGPOvrd_143h 0;
BA_ "GenSigSendType" SG_ 323 HCU_CRC2_143h 0;
BA_ "GenSigSendType" SG_ 323 HCU_RollgCntr2_143h 0;
BA_ "GenSigSendType" SG_ 323 HCU_Resd2_143h 0;
BA_ "ASIL" SG_ 323 HCU_FMCUStandstill_143h 2;
BA_ "GenSigSendType" SG_ 323 HCU_FMCUStandstill_143h 0;
BA_ "ASIL" SG_ 323 HCU_FMCUModActvSt_143h 2;
BA_ "GenSigSendType" SG_ 323 HCU_FMCUModActvSt_143h 0;
BA_ "ASIL" SG_ 323 HCU_FMCU_SpdSvModAvl_143h 2;
BA_ "GenSigSendType" SG_ 323 HCU_FMCU_SpdSvModAvl_143h 0;
BA_ "ASIL" SG_ 323 HCU_FMCU_ModeSt_143h 3;
BA_ "GenSigSendType" SG_ 323 HCU_FMCU_ModeSt_143h 0;
BA_ "GenSigInvalidValue" SG_ 323 HCU_FMCU_SpdAct_143h 65535;
BA_ "GenSigStartValue" SG_ 323 HCU_FMCU_SpdAct_143h 32767;
BA_ "ASIL" SG_ 323 HCU_FMCU_SpdAct_143h 3;
BA_ "GenSigSendType" SG_ 323 HCU_FMCU_SpdAct_143h 0;
BA_ "ASIL" SG_ 323 HCU_FMCUActRUnfilteredRodSpd 2;
BA_ "GenSigSendType" SG_ 323 HCU_FMCUActRUnfilteredRodSpd 0;
BA_ "GenSigSendType" SG_ 323 HCU_FMCUSpdActVld_143h 0;
BA_ "GenSigSendType" SG_ 323 HCU_FMCUSpdSVModFlt_143h 0;
BA_ "ASIL" SG_ 323 HCU_FMCUVehSldSt_143h 2;
BA_ "GenSigSendType" SG_ 323 HCU_FMCUVehSldSt_143h 0;
BA_ "ASIL" SG_ 323 HCU_FMCUBlkSt_143h 2;
BA_ "GenSigSendType" SG_ 323 HCU_FMCUBlkSt_143h 0;
BA_ "GenSigSendType" SG_ 323 HCU_CRC3_143h 0;
BA_ "GenSigSendType" SG_ 323 HCU_RollgCntr3_143h 0;
BA_ "GenSigSendType" SG_ 323 HCU_Resd3_143h 0;
BA_ "GenSigSendType" SG_ 323 HCU_ISGStandstill_143h 0;
BA_ "GenSigSendType" SG_ 323 HCU_ISGModActvSt_143h 0;
BA_ "GenSigSendType" SG_ 323 HCU_ISGSpdSvModAvl_143h 0;
BA_ "ASIL" SG_ 323 HCU_ISGF_ModeSt_143h 1;
BA_ "GenSigSendType" SG_ 323 HCU_ISGF_ModeSt_143h 0;
BA_ "GenSigInvalidValue" SG_ 323 HCU_ISGF_SpdAct_143h 65535;
BA_ "GenSigStartValue" SG_ 323 HCU_ISGF_SpdAct_143h 32767;
BA_ "ASIL" SG_ 323 HCU_ISGF_SpdAct_143h 1;
BA_ "GenSigSendType" SG_ 323 HCU_ISGF_SpdAct_143h 0;
BA_ "GenSigSendType" SG_ 323 HCU_ISGActRUnfilteredRodSpd 0;
BA_ "GenSigSendType" SG_ 323 HCU_ISGF_SpdActVld_143h 0;
BA_ "GenSigSendType" SG_ 323 HCU_ISGSpdSVModFlt_143h 0;
BA_ "GenSigSendType" SG_ 323 HCU_ISGVehSldSt_143h 0;
BA_ "GenSigSendType" SG_ 323 HCU_ISGBlkSt_143h 0;
BA_ "GenSigSendType" SG_ 323 HCU_CRC4_143h 0;
BA_ "GenSigSendType" SG_ 323 HCU_RollgCntr4_143h 0;
BA_ "GenSigSendType" SG_ 323 HCU_Resd4_143h 0;
BA_ "GenSigSendType" SG_ 323 HCU_RMCUStandstill_143h 0;
BA_ "GenSigSendType" SG_ 323 HCU_RMCUModActvSt_143h 0;
BA_ "GenSigSendType" SG_ 323 HCU_RMCU_SpdSvModAvl_143h 0;
BA_ "GenSigSendType" SG_ 323 HCU_RMCU_State_143h 0;
BA_ "GenSigInvalidValue" SG_ 323 HCU_RMCU_Speed_143h 65535;
BA_ "GenSigStartValue" SG_ 323 HCU_RMCU_Speed_143h 32767;
BA_ "ASIL" SG_ 323 HCU_RMCU_Speed_143h 3;
BA_ "GenSigSendType" SG_ 323 HCU_RMCU_Speed_143h 0;
BA_ "GenSigSendType" SG_ 323 HCU_RMCUActRUnfilteredRodSpd 0;
BA_ "GenSigSendType" SG_ 323 HCU_RMCU_SpeedVld_143h 0;
BA_ "GenSigSendType" SG_ 323 HCU_RMCUSpdSVModFlt_143h 0;
BA_ "GenSigSendType" SG_ 323 HCU_RMCUVehSldSt_143h 0;
BA_ "GenSigSendType" SG_ 323 HCU_RMCU_MCUBlkSt_143h 0;
BA_ "GenSigSendType" SG_ 323 HCU_CRC5_143h 0;
BA_ "GenSigSendType" SG_ 323 HCU_RollgCntr5_143h 0;
BA_ "GenSigSendType" SG_ 323 HCU_Resd5_143h 0;
BA_ "GenSigSendType" SG_ 323 HCU_RMCUReqTq_143h 0;
BA_ "GenSigSendType" SG_ 323 HCU_FMCUReqTq_143h 0;
BA_ "GenSigSendType" SG_ 323 HCU_ISGFReqTq_143h 0;
BA_ "GenSigSendType" SG_ 323 HCU_CRC6_143h 0;
BA_ "GenSigSendType" SG_ 323 HCU_RollgCntr6_143h 0;
BA_ "GenSigSendType" SG_ 323 HCU_Resd6_143h 0;
BA_ "GenSigStartValue" SG_ 324 VCU_MotorDrvCaplTqWhlFA 32768;
BA_ "GenSigSendType" SG_ 324 VCU_MotorDrvCaplTqWhlFA 0;
BA_ "GenSigStartValue" SG_ 324 VCU_MotorRgnCaplTqWhlFA 32768;
BA_ "GenSigSendType" SG_ 324 VCU_MotorRgnCaplTqWhlFA 0;
BA_ "GenSigStartValue" SG_ 324 VCU_MotorDrvCaplTqWhlRA 32768;
BA_ "GenSigSendType" SG_ 324 VCU_MotorDrvCaplTqWhlRA 0;
BA_ "GenSigStartValue" SG_ 324 VCU_MotorRgnCaplTqWhlRA 32768;
BA_ "GenSigSendType" SG_ 324 VCU_MotorRgnCaplTqWhlRA 0;
BA_ "GenSigSendType" SG_ 555 ONEBOX_3_CRC4 0;
BA_ "GenSigSendType" SG_ 555 ONEBOX_3_RollgCntr4 0;
BA_ "GenSigSendType" SG_ 555 ONEBOX_3_Resd4 0;
BA_ "ASIL" SG_ 555 BrakePedalPressStsValidData 4;
BA_ "GenSigSendType" SG_ 555 BrakePedalPressStsValidData 0;
BA_ "ASIL" SG_ 555 BrakePedalPressSts 4;
BA_ "GenSigSendType" SG_ 555 BrakePedalPressSts 0;
BA_ "GenSigSendType" SG_ 1204 VCU_1_G_CRC 0;
BA_ "GenSigSendType" SG_ 1204 VCU_1_G_RollgCntr 0;
BA_ "GenSigSendType" SG_ 1204 VCU_AcceleratorPosRawIVD 0;
BA_ "GenSigStartValue" SG_ 1204 VCU_1_G_Pwr 500;
BA_ "GenSigSendType" SG_ 1204 VCU_1_G_Pwr 0;
BA_ "ASIL" SG_ 1204 VCU_1_G_AcceleratorPosRaw 2;
BA_ "GenSigSendType" SG_ 1204 VCU_1_G_AcceleratorPosRaw 0;
BA_ "ASIL" SG_ 1204 VCU_1_G_PTReady 2;
BA_ "GenSigSendType" SG_ 1204 VCU_1_G_PTReady 0;
BA_ "GenSigStartValue" SG_ 1204 VCU_1_G_DriveMode 6;
BA_ "ASIL" SG_ 1204 VCU_1_G_DriveMode 2;
BA_ "GenSigSendType" SG_ 1204 VCU_1_G_DriveMode 0;
BA_ "GenSigSendType" SG_ 1204 VCU_1_G_BookChrgSetResponse 0;
BA_ "GenSigSendType" SG_ 1204 VCU_1_G_HvBattKeepWarmSts 0;
BA_ "GenSigSendType" SG_ 1204 VCU_1_G_HvBattKeepWarmActiveReq 0;
BA_ "GenSigInvalidValue" SG_ 1204 VCU_1_G_HundECAver 511;
BA_ "GenSigSendType" SG_ 1204 VCU_1_G_HundECAver 0;
BA_ "GenSigSendType" SG_ 1204 VCU_1_G_BookChrgSetStsFb 0;
BA_ "GenSigSendType" SG_ 1204 VCU_1_G_EgyRegenLevel 0;
BA_ "ASIL" SG_ 1204 VCU_1_G_PRNDGearAct 2;
BA_ "GenSigSendType" SG_ 1204 VCU_1_G_PRNDGearAct 0;
BA_ "GenSigSendType" SG_ 1209 VCU_2_G_CRC 0;
BA_ "GenSigSendType" SG_ 1209 VCU_2_G_RollgCntr 0;
BA_ "GenSigSendType" SG_ 1209 VCU_2_G_Resd 0;
BA_ "GenSigInvalidValue" SG_ 1209 VCU_2_G_GasPedalPosInvalidData 1;
BA_ "ASIL" SG_ 1209 VCU_2_G_GasPedalPosInvalidData 2;
BA_ "GenSigSendType" SG_ 1209 VCU_2_G_GasPedalPosInvalidData 0;
BA_ "ASIL" SG_ 1209 VCU_2_G_PowerLimit 2;
BA_ "GenSigSendType" SG_ 1209 VCU_2_G_PowerLimit 0;
BA_ "GenSigSendType" SG_ 1209 VCU_2_G_BrakeLightReq 0;
BA_ "ASIL" SG_ 1209 VCU_2_G_VehicleSystemFailure 2;
BA_ "GenSigSendType" SG_ 1209 VCU_2_G_VehicleSystemFailure 0;
BA_ "GenSigSendType" SG_ 1209 OnekeyHVOffSuccess_4B9h 0;
BA_ "GenSigSendType" SG_ 1209 VCU_2_G_BootloadSts 0;
BA_ "GenSigSendType" SG_ 1209 VCU_2_G_DischgSts 0;
BA_ "GenSigSendType" SG_ 1209 VCU_2_G_BrakePedalStsValidData 0;
BA_ "GenSigSendType" SG_ 1209 VCU_2_G_ExhibitionMod 0;
BA_ "ASIL" SG_ 1209 VCU_2_G_BrakePedalSts 2;
BA_ "GenSigSendType" SG_ 1209 VCU_2_G_BrakePedalSts 0;
BA_ "GenSigSendType" SG_ 1209 VCU_2_G_DCDCEnable 0;
BA_ "ASIL" SG_ 1209 VCU_2_G_HVReady 2;
BA_ "GenSigSendType" SG_ 1209 VCU_2_G_HVReady 0;
BA_ "GenSigSendType" SG_ 1209 Res_VCU_2_G_Brake_state 0;
BA_ "GenSigSendType" SG_ 1209 VCU_2_G_VCUEnergyflow 0;
BA_ "GenSigInvalidValue" SG_ 1209 VCU_2_G_GasPedalPosition 1023;
BA_ "ASIL" SG_ 1209 VCU_2_G_GasPedalPosition 2;
BA_ "GenSigSendType" SG_ 1209 VCU_2_G_GasPedalPosition 0;
BA_ "GenSigSendType" SG_ 1209 VCU_2_G_DrvGearShiftFailureIndcn 0;
BA_ "GenSigSendType" SG_ 1209 VCU_2_G_OnekeyHVoffStyle 0;
BA_ "GenSigStartValue" SG_ 1582 srcNodeID_RMCU 46;
BA_ "GenSigSendType" SG_ 1582 srcNodeID_RMCU 0;
BA_ "GenSigSendType" SG_ 1582 RMR_RMCU 0;
BA_ "GenSigSendType" SG_ 1582 NMm_RMCU_Reserved1 0;
BA_ "GenSigSendType" SG_ 1582 RMCU_Wakeup_Poweron 0;
BA_ "GenSigSendType" SG_ 1582 RMCU_Wakeup_NM 0;
BA_ "GenSigSendType" SG_ 1582 RMCU_Wakeup_Diag 0;
BA_ "GenSigSendType" SG_ 1582 RMCU_Awake_Poweron 0;
BA_ "GenSigSendType" SG_ 1582 RMCU_Awake_NM 0;
BA_ "GenSigSendType" SG_ 1582 RMCU_Awake_Diag 0;
BA_ "GenSigSendType" SG_ 1582 RMCU_Awake_Discharge 0;
BA_ "GenSigSendType" SG_ 1582 RMCU_Awake_HVON 0;
VAL_ 56 VCU_10_ShiftInProgress 0 "Not in progress" 1 "In progress";
VAL_ 56 VCU_10_ShiftInProgressValidData 0 "Not Valid" 1 "V alid";
VAL_ 56 VCU_10_TargetGear 0 "No Request" 1 "Target gear P" 2 "Target gear R" 3 "Target gear N" 4 "Target gear D" 5 "Reserved" 6 "Reserved" 7 "Invalid";
VAL_ 56 VCU_10_ActualGear 0 "No Request" 1 "gear P" 2 "gear R" 3 "gear N" 4 "gear D" 5 "Reserved" 6 "Reserved" 7 "Invalid";
VAL_ 56 VCU_10_TargetGearValidData 0 "Not Valid" 1 "V alid";
VAL_ 56 VCU_10_ActualGearValidData 0 "Not Valid" 1 "V alid";
VAL_ 56 VCU_10_BrakePedalStsValidData 0 "Valid" 1 "Not Valid";
VAL_ 56 VCU_10_BrakePedalSts 0 "Not applied" 1 "Applied";
VAL_ 56 VCU_10_TowingMode 0 "NotActive" 1 "Active" 2 "Reserved" 3 "Reserved";
VAL_ 56 HCU_TCUR_GearShiftProgFlag 0 "No shift" 1 "Shift in processing" 2 "Shift success" 3 "Shift failed";
VAL_ 59 VCU_11_ActWheelSpdFA 65535 "Invalid";
VAL_ 59 VCU_11_IndcdDriverReqWhlTqStsFA 0 "no failure" 1 "failure";
VAL_ 59 VCU_11_ActWheelTorqueStsFA 0 "no failure" 1 "failure";
VAL_ 59 VCU_11_ActWheelSpdStsFA 0 "no failure" 1 "failure";
VAL_ 59 VCU_11_MotorReadyFMCU 0 "Not Ready" 1 "Ready";
VAL_ 59 VCU_11_ActWheelSpdRA 65535 "Invalid";
VAL_ 59 VCU_11_IndcdDriverReqWhlTqStsRA 0 "no failure" 1 "failure";
VAL_ 59 VCU_11_ActWheelTorqueStsRA 0 "no failure" 1 "failure";
VAL_ 59 VCU_11_MotorReadyRMCU 0 "Not Ready" 1 "Ready";
VAL_ 59 VCU_11_ActWheelSpdStsRA 0 "no failure" 1 "failure";
VAL_ 59 VCU_11_MbRegenMaxWheelQualifier 0 "NotIntialized" 1 "Normal" 2 "Faulty" 3 "Reserved";
VAL_ 59 VCU_11_MbRegenWheelQualifier 0 "NotIntialized" 1 "Normal" 2 "Faulty" 3 "Reserved";
VAL_ 59 VCU_11_EPBReq 0 "no request" 1 "Release" 2 "Close";
VAL_ 59 VCU_11_GasPedalPosInvalidData 0 "Valid" 1 "Invalid";
VAL_ 59 VCU_11_AcceleratorPosRawIVD 0 "Valid" 1 "Invalid";
VAL_ 59 VCU_11_GasPedalPosition 1023 "Invalid";
VAL_ 59 VCU_11_AcceleratorPosRaw 1023 "Invalid";
VAL_ 59 VCU_11_EPBReqValid 0 "Valid" 1 "Invalid";
VAL_ 59 VCU_11_CoastRegenTargetWheelFAQ 0 "NotIntialized" 1 "Normal" 2 "Faulty" 3 "Reserved";
VAL_ 59 VCU_11_CoastRegenTargetWheelRAQ 0 "NotIntialized" 1 "Normal" 2 "Faulty" 3 "Reserved";
VAL_ 59 VCU_11_OPDHoldRequest 0 "No request" 1 "Hold request" 2 "Drive off(Reserved)" 3 "Reserved";
VAL_ 59 VCU_11_OPDHydBrkCompenRqSts 0 "No request" 1 "Request hydraulic compensation";
VAL_ 59 VCU_11_OnePedalstatus 0 "OFF" 1 "ON";
VAL_ 59 HCU_11_RearWheelDir 0 "Undefinable" 1 "Forward" 2 "Backward" 3 "Reserved";
VAL_ 59 VCU_11_DrivingModReq 0 "Normal" 1 "Snow" 2 "Mud" 3 "Sand" 4 "Rock" 5 "Wade" 6 "Expert" 7 "UTURN" 8 "DRIFT" 9 "OffroadRace" 10 "DCM" 11 "Reserved" 12 "Reserved" 13 "Reserved" 14 "Reserved" 15 "Reserved" 16 "Reserved" 17 "Reserved" 18 "Reserved" 19 "Reserved" 20 "Reserved" 21 "Reserved" 22 "Reserved" 23 "Reserved" 24 "Reserved" 25 "Reserved" 26 "Reserved" 27 "Reserved" 28 "Reserved" 29 "Reserved" 30 "Reserved" 31 "Reserved";
VAL_ 323 HCU_ErrorFb_143h 0 "No error" 1 "ADS Req Invalid" 2 "HV Fault" 3 "MCU Fault" 4 "BMSFault" 5 "ADS E2E Fault or Time out Fault";
VAL_ 323 HCU_GearShiftAvl_143h 0 "Not available" 1 "Available";
VAL_ 323 HCU_VehWhlReqTqVld_143h 0 "Invalid" 1 "Valid";
VAL_ 323 HCU_EGSGearShiftReq_143h 0 "P" 1 "R" 2 "N" 3 "D";
VAL_ 323 HCU_CIMGearShiftReq_143h 0 "P档" 1 "R档" 2 "N档" 3 "D档" 4 "Reserved" 5 "Reserved" 6 "Reserved" 7 "Reserved";
VAL_ 323 HCU_ECGPOvrdInvalidData_143h 0 "Valid" 1 "Invalid";
VAL_ 323 HCU_ECGPOvrd_143h 0 "No Override" 1 "Driver Override";
VAL_ 323 HCU_FMCUStandstill_143h 0 "No Standstill" 1 "Standstill";
VAL_ 323 HCU_FMCUModActvSt_143h 0 "Torque mode" 1 "Speed mode" 2 "SV mode";
VAL_ 323 HCU_FMCU_SpdSvModAvl_143h 0 "Invalid" 1 "Valid";
VAL_ 323 HCU_FMCU_ModeSt_143h 0 "INIT (Initialization)" 1 "Standby" 2 "HV Ready" 3 "Tq Control" 4 "Activeheat_Mode" 5 "Boost_Mode(Reserved)" 6 "PowerDown" 7 "Afterrun" 8 "Fault" 9 "Volt Control(Reserved)" 10 "Spd Control(Reserved)" 11 "Offset Calibration(DHT)" 12 "reserved" 13 "reserved" 14 "reserved" 15 "reserved";
VAL_ 323 HCU_FMCU_SpdAct_143h 65535 "Invalid";
VAL_ 323 HCU_FMCUSpdActVld_143h 0 "Valid" 1 "Invalid";
VAL_ 323 HCU_FMCUSpdSVModFlt_143h 0 "No Error" 1 "Absolute value of output torque  too large";
VAL_ 323 HCU_FMCUVehSldSt_143h 0 "No Slide" 1 "Slide";
VAL_ 323 HCU_FMCUBlkSt_143h 0 "No Stalling" 1 "Stalling";
VAL_ 323 HCU_ISGStandstill_143h 0 "No Standstill" 1 "Standstill";
VAL_ 323 HCU_ISGModActvSt_143h 0 "Torque mode" 1 "Speed mode" 2 "SV mode";
VAL_ 323 HCU_ISGSpdSvModAvl_143h 0 "Invalid" 1 "Valid";
VAL_ 323 HCU_ISGF_ModeSt_143h 0 "INIT (Initialization)" 1 "LV Standby (Precharge)" 2 "HV Standby (Disable)" 3 "Tq Control" 4 "Volt Control" 5 "Spd Control" 6 "Offset Calibration" 7 "Powerdown (Discharge)" 8 "Afterrun" 9 "Failure" 10 "Off" 11 "Service" 12 "Cur Control(Reserved)" 13 "reserved" 14 "reserved" 15 "reserved";
VAL_ 323 HCU_ISGF_SpdAct_143h 65535 "Invalid";
VAL_ 323 HCU_ISGF_SpdActVld_143h 0 "Valid" 1 "Invalid";
VAL_ 323 HCU_ISGSpdSVModFlt_143h 0 "No Error" 1 "Absolute value of output torque  too large";
VAL_ 323 HCU_ISGVehSldSt_143h 0 "No Slide" 1 "Slide";
VAL_ 323 HCU_ISGBlkSt_143h 0 "No Stalling" 1 "Stalling";
VAL_ 323 HCU_RMCUStandstill_143h 0 "No Standstill" 1 "Standstill";
VAL_ 323 HCU_RMCUModActvSt_143h 0 "Torque mode" 1 "Speed mode" 2 "SV mode";
VAL_ 323 HCU_RMCU_SpdSvModAvl_143h 0 "Invalid" 1 "Valid";
VAL_ 323 HCU_RMCU_State_143h 0 "INIT (Initialization)" 1 "Standby" 2 "HV Ready" 3 "Tq Control" 4 "Activeheat_Mode" 5 "Boost_Mode" 6 "PowerDown" 7 "Afterrun" 8 "Fault" 9 "Volt Control(Reserved)" 10 "Spd Control(Reserved)" 11 "reserved" 12 "reserved" 13 "reserved" 14 "reserved" 15 "reserved";
VAL_ 323 HCU_RMCU_Speed_143h 65535 "Invalid";
VAL_ 323 HCU_RMCU_SpeedVld_143h 0 "Valid" 1 "Invalid";
VAL_ 323 HCU_RMCUSpdSVModFlt_143h 0 "No Error" 1 "Absolute value of output torque  too large";
VAL_ 323 HCU_RMCUVehSldSt_143h 0 "No Slide" 1 "Slide";
VAL_ 323 HCU_RMCU_MCUBlkSt_143h 0 "No Stalling" 1 "Stalling";
VAL_ 555 BrakePedalPressStsValidData 0 "Valid" 1 "Invalid";
VAL_ 555 BrakePedalPressSts 0 "Not Active" 1 "Not Pressed" 2 "Pressed" 3 "Error";
VAL_ 1204 VCU_AcceleratorPosRawIVD 0 "Valid" 1 "Invalid";
VAL_ 1204 VCU_1_G_PTReady 0 "LmpOFF" 1 "LmpON";
VAL_ 1204 VCU_1_G_DriveMode 0 "Not Active" 1 "ECO" 2 "Normal" 3 "Sport" 4 "Snow" 5 "Off Road" 6 "Individual" 7 "Reserved";
VAL_ 1204 VCU_1_G_BookChrgSetResponse 0 "Default" 1 "Success" 2 "Cancelled" 3 "Fail" 4 "Reserved";
VAL_ 1204 VCU_1_G_HvBattKeepWarmSts 0 "NotWarm" 1 "Warming" 2 "ExitWarm" 3 "WarmCompete" 4 "Reserved" 5 "Reserved" 6 "Reserved" 7 "Reserved";
VAL_ 1204 VCU_1_G_HvBattKeepWarmActiveReq 0 "default" 1 "StartWarm" 2 "EndWarm" 3 "Reserved";
VAL_ 1204 VCU_1_G_HundECAver 511 "Invalid";
VAL_ 1204 VCU_1_G_BookChrgSetStsFb 0 "NotBook" 1 "Booked" 2 "Reserved";
VAL_ 1204 VCU_1_G_EgyRegenLevel 0 "Off" 1 "Low" 2 "High" 3 "Reserved";
VAL_ 1204 VCU_1_G_PRNDGearAct 0 "Init" 1 "P" 2 "R" 3 "N" 4 "D" 5 "Reserved" 6 "Reserved" 7 "Reserved";
VAL_ 1209 VCU_2_G_GasPedalPosInvalidData 0 "Valid" 1 "Invalid";
VAL_ 1209 VCU_2_G_PowerLimit 0 "LmpOFF" 1 "LmpON";
VAL_ 1209 VCU_2_G_BrakeLightReq 0 "LmpOFF" 1 "LmpON";
VAL_ 1209 VCU_2_G_VehicleSystemFailure 0 "Fail not present" 1 "Fail present";
VAL_ 1209 OnekeyHVOffSuccess_4B9h 0 "Not Success" 1 "Success";
VAL_ 1209 VCU_2_G_BootloadSts 0 "No Display" 1 "Display";
VAL_ 1209 VCU_2_G_DischgSts 0 "No Active" 1 "Active";
VAL_ 1209 VCU_2_G_BrakePedalStsValidData 0 "Valid" 1 "Not Valid";
VAL_ 1209 VCU_2_G_ExhibitionMod 0 "No Active" 1 "Active";
VAL_ 1209 VCU_2_G_BrakePedalSts 0 "Not applied" 1 "Applied";
VAL_ 1209 VCU_2_G_DCDCEnable 0 "Disable" 1 "Enable";
VAL_ 1209 VCU_2_G_HVReady 0 "LmpOFF" 1 "LmpON";
VAL_ 1209 Res_VCU_2_G_Brake_state 0 "Not braking" 1 "Braking";
VAL_ 1209 VCU_2_G_VCUEnergyflow 0 "NotHvReady" 1 "charging" 2 "RWD" 3 "recycle" 4 "external_discharge" 5 "battery_heat" 6 "AWD" 7 "FWD" 8 "HV_ON" 9 "Reserved";
VAL_ 1209 VCU_2_G_GasPedalPosition 1023 "Invalid";
VAL_ 1209 VCU_2_G_DrvGearShiftFailureIndcn 0 "No Command" 1 "rake pedal applied" 2 "Over Speed" 3 "Charge Gun Connect" 4 "EPB Can Not Lock" 5 "EPB Can Not Release" 6 "Invalid shift" 7 "Shift fault";
VAL_ 1209 VCU_2_G_OnekeyHVoffStyle 0 "NotActive" 1 "Independent" 2 "Park Button";
VAL_ 1582 RMR_RMCU 0 "Inactive" 1 "Active";
VAL_ 1582 RMCU_Wakeup_Poweron 0 "Inactive" 1 "Active";
VAL_ 1582 RMCU_Wakeup_NM 0 "Inactive" 1 "Active";
VAL_ 1582 RMCU_Wakeup_Diag 0 "Inactive" 1 "Active";
VAL_ 1582 RMCU_Awake_Poweron 0 "Inactive" 1 "Active";
VAL_ 1582 RMCU_Awake_NM 0 "Inactive" 1 "Active";
VAL_ 1582 RMCU_Awake_Diag 0 "Inactive" 1 "Active";
VAL_ 1582 RMCU_Awake_Discharge 0 "Inactive" 1 "Active";
VAL_ 1582 RMCU_Awake_HVON 0 "Inactive" 1 "Active";
